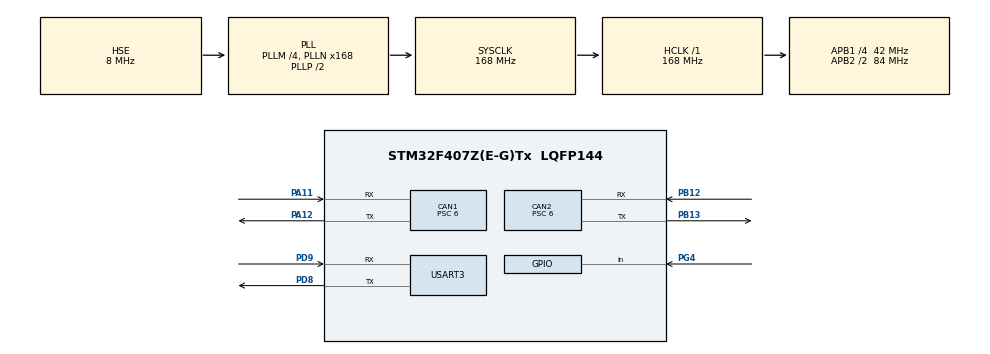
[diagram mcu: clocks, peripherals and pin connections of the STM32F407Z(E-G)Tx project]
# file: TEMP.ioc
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CAN1.BS1=CAN_BS1_3TQ
CAN1.BS2=CAN_BS2_3TQ
CAN1.CalculateBaudRate=1000000
CAN1.CalculateTimeBit=1000
CAN1.CalculateTimeQuantum=142.85714285714286
CAN1.Prescaler=6
CAN1.SJW=CAN_SJW_4TQ
CAN2.BS1=CAN_BS1_3TQ
CAN2.BS2=CAN_BS2_3TQ
CAN2.CalculateBaudRate=1000000
CAN2.CalculateTimeBit=1000
CAN2.CalculateTimeQuantum=142.85714285714286
CAN2.Prescaler=6
CAN2.SJW=CAN_SJW_4TQ
FREERTOS.Tasks01=defaultTask,24,128,StartDefaultTask,Default,NULL,Dynamic,NULL,NULL;myTask02,8,128,TX,As external,NULL,Dynamic,NULL,NULL;myTask03,8,128,CALCULATE,As external,NULL,Dynamic,NULL,NULL;myTask04,8,128,StartTask04,Default,NULL,Dynamic,NULL,NULL
Mcu.Family=STM32F4
Mcu.Name=STM32F407Z(E-G)Tx
Mcu.Package=LQFP144
NVIC.CAN1_RX0_IRQn=true\:5\:0\:false\:false\:true\:true\:true\:true\:true
NVIC.CAN1_TX_IRQn=true\:5\:0\:false\:false\:true\:true\:true\:true\:true
NVIC.CAN2_RX0_IRQn=true\:5\:0\:false\:false\:true\:true\:true\:true\:true
NVIC.CAN2_TX_IRQn=true\:5\:0\:false\:false\:true\:true\:true\:true\:true
NVIC.PriorityGroup=NVIC_PRIORITYGROUP_4
NVIC.TIM1_UP_TIM10_IRQn=true\:15\:0\:false\:false\:true\:false\:false\:true\:true
NVIC.TimeBase=TIM1_UP_TIM10_IRQn
NVIC.TimeBaseIP=TIM1
PA11.Mode=CAN_Activate
PA11.Signal=CAN1_RX
PA12.Mode=CAN_Activate
PA12.Signal=CAN1_TX
PA13.Mode=Serial_Wire
PA13.Signal=SYS_JTMS-SWDIO
PA14.Mode=Serial_Wire
PA14.Signal=SYS_JTCK-SWCLK
PB12.Mode=CAN_Activate
PB12.Signal=CAN2_RX
PB13.Mode=CAN_Activate
PB13.Signal=CAN2_TX
PD8.Mode=Asynchronous
PD8.Signal=USART3_TX
PD9.Mode=Asynchronous
PD9.Signal=USART3_RX
PG4.Signal=GPIO_Input
PH0-OSC_IN.Mode=HSE-External-Oscillator
PH0-OSC_IN.Signal=RCC_OSC_IN
PH1-OSC_OUT.Mode=HSE-External-Oscillator
PH1-OSC_OUT.Signal=RCC_OSC_OUT
ProjectManager.HeapSize=0x200
ProjectManager.StackSize=0x400
ProjectManager.TargetToolchain=MDK-ARM V5.32
RCC.48MHZClocksFreq_Value=84000000
RCC.AHBFreq_Value=168000000
RCC.APB1CLKDivider=RCC_HCLK_DIV4
RCC.APB1Freq_Value=42000000
RCC.APB1TimFreq_Value=84000000
RCC.APB2CLKDivider=RCC_HCLK_DIV2
RCC.APB2Freq_Value=84000000
RCC.APB2TimFreq_Value=168000000
RCC.CortexFreq_Value=168000000
RCC.HCLKFreq_Value=168000000
RCC.HSE_VALUE=8000000
RCC.HSI_VALUE=16000000
RCC.LSE_VALUE=32768
RCC.PLLM=4
RCC.PLLN=168
RCC.PLLSourceVirtual=RCC_PLLSOURCE_HSE
RCC.SYSCLKFreq_VALUE=168000000
RCC.SYSCLKSource=RCC_SYSCLKSOURCE_PLLCLK
RCC.VCOOutputFreq_Value=336000000
USART3.VirtualMode=VM_ASYNC
VP_FREERTOS_VS_CMSIS_V2.Mode=CMSIS_V2
VP_SYS_VS_tim1.Mode=TIM1
board=custom

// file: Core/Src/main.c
/* USER CODE BEGIN Header */
/**
  ******************************************************************************
  * @file           : main.c
  * @brief          : Main program body
  ******************************************************************************
  * @attention
  *
  * Copyright (c) 2024 STMicroelectronics.
  * All rights reserved.
  *
  * This software is licensed under terms that can be found in the LICENSE file
  * in the root directory of this software component.
  * If no LICENSE file comes with this software, it is provided AS-IS.
  *
  ******************************************************************************
  */
/* USER CODE END Header */
#include "main.h"
#include "cmsis_os.h"
#include "can.h"
#include "usart.h"
#include "gpio.h"

/* USER CODE BEGIN Includes */
#include "can_rec.h"
/* USER CODE END Includes */

void SystemClock_Config(void);
void MX_FREERTOS_Init(void);

int main(void)
{

  /* MCU Configuration--------------------------------------------------------*/

  /* Reset of all peripherals, Initializes the Flash interface and the Systick. */
  HAL_Init();

  /* Configure the system clock */
  SystemClock_Config();

  /* Initialize all configured peripherals */
  MX_GPIO_Init();
  MX_CAN1_Init();
  MX_CAN2_Init();
  MX_USART3_UART_Init();
  /* USER CODE BEGIN 2 */
	    my_can_filter_init_recv_all(&hcan1);
    __HAL_CAN_ENABLE_IT(&hcan1, CAN_IT_RX_FIFO0_MSG_PENDING);
//    my_can_filter_init_recv_all(&hcan2);
//    __HAL_CAN_ENABLE_IT(&hcan2, CAN_IT_RX_FIFO0_MSG_PENDING);
  /* USER CODE END 2 */

  /* Init scheduler */
  osKernelInitialize();

  /* Call init function for freertos objects (in cmsis_os2.c) */
  MX_FREERTOS_Init();

  /* Start scheduler */
  osKernelStart();

  /* We should never get here as control is now taken by the scheduler */

  /* Infinite loop */
  while (1)
  {

  }
}

void SystemClock_Config(void)
{
  RCC_OscInitTypeDef RCC_OscInitStruct = {0};
  RCC_ClkInitTypeDef RCC_ClkInitStruct = {0};

  /** Configure the main internal regulator output voltage
  */
  __HAL_RCC_PWR_CLK_ENABLE();
  __HAL_PWR_VOLTAGESCALING_CONFIG(PWR_REGULATOR_VOLTAGE_SCALE1);

  /** Initializes the RCC Oscillators according to the specified parameters
  * in the RCC_OscInitTypeDef structure.
  */
  RCC_OscInitStruct.OscillatorType = RCC_OSCILLATORTYPE_HSE;
  RCC_OscInitStruct.HSEState = RCC_HSE_ON;
  RCC_OscInitStruct.PLL.PLLState = RCC_PLL_ON;
  RCC_OscInitStruct.PLL.PLLSource = RCC_PLLSOURCE_HSE;
  RCC_OscInitStruct.PLL.PLLM = 4;
  RCC_OscInitStruct.PLL.PLLN = 168;
  RCC_OscInitStruct.PLL.PLLP = RCC_PLLP_DIV2;
  RCC_OscInitStruct.PLL.PLLQ = 4;
  if (HAL_RCC_OscConfig(&RCC_OscInitStruct) != HAL_OK)
  {
    Error_Handler();
  }

  /** Initializes the CPU, AHB and APB buses clocks
  */
  RCC_ClkInitStruct.ClockType = RCC_CLOCKTYPE_HCLK|RCC_CLOCKTYPE_SYSCLK
                              |RCC_CLOCKTYPE_PCLK1|RCC_CLOCKTYPE_PCLK2;
  RCC_ClkInitStruct.SYSCLKSource = RCC_SYSCLKSOURCE_PLLCLK;
  RCC_ClkInitStruct.AHBCLKDivider = RCC_SYSCLK_DIV1;
  RCC_ClkInitStruct.APB1CLKDivider = RCC_HCLK_DIV4;
  RCC_ClkInitStruct.APB2CLKDivider = RCC_HCLK_DIV2;

  if (HAL_RCC_ClockConfig(&RCC_ClkInitStruct, FLASH_LATENCY_5) != HAL_OK)
  {
    Error_Handler();
  }
}

void HAL_TIM_PeriodElapsedCallback(TIM_HandleTypeDef *htim)
{
  if (htim->Instance == TIM1) {
    HAL_IncTick();
  }
}

void Error_Handler(void)
{
  __disable_irq();
  while (1)
  {
  }
}

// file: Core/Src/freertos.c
/* USER CODE BEGIN Header */
/**
  ******************************************************************************
  * File Name          : freertos.c
  * Description        : Code for freertos applications
  ******************************************************************************
  * @attention
  *
  * Copyright (c) 2024 STMicroelectronics.
  * All rights reserved.
  *
  * This software is licensed under terms that can be found in the LICENSE file
  * in the root directory of this software component.
  * If no LICENSE file comes with this software, it is provided AS-IS.
  *
  ******************************************************************************
  */
/* USER CODE END Header */

#include "FreeRTOS.h"
#include "task.h"
#include "main.h"
#include "cmsis_os.h"

/* Definitions for defaultTask */
osThreadId_t defaultTaskHandle;
const osThreadAttr_t defaultTask_attributes = {
  .name = "defaultTask",
  .stack_size = 128 * 4,
  .priority = (osPriority_t) osPriorityNormal,
};
/* Definitions for myTask02 */
osThreadId_t myTask02Handle;
const osThreadAttr_t myTask02_attributes = {
  .name = "myTask02",
  .stack_size = 128 * 4,
  .priority = (osPriority_t) osPriorityLow,
};
/* Definitions for myTask03 */
osThreadId_t myTask03Handle;
const osThreadAttr_t myTask03_attributes = {
  .name = "myTask03",
  .stack_size = 128 * 4,
  .priority = (osPriority_t) osPriorityLow,
};
/* Definitions for myTask04 */
osThreadId_t myTask04Handle;
const osThreadAttr_t myTask04_attributes = {
  .name = "myTask04",
  .stack_size = 128 * 4,
  .priority = (osPriority_t) osPriorityLow,
};

void StartDefaultTask(void *argument);
extern void TX(void *argument);
extern void CALCULATE(void *argument);
void StartTask04(void *argument);

void MX_FREERTOS_Init(void); /* (MISRA C 2004 rule 8.1) */

void MX_FREERTOS_Init(void) {

  /* Create the thread(s) */
  /* creation of defaultTask */
  defaultTaskHandle = osThreadNew(StartDefaultTask, NULL, &defaultTask_attributes);

  /* creation of myTask02 */
  myTask02Handle = osThreadNew(TX, NULL, &myTask02_attributes);

  /* creation of myTask03 */
  myTask03Handle = osThreadNew(CALCULATE, NULL, &myTask03_attributes);

  /* creation of myTask04 */
  myTask04Handle = osThreadNew(StartTask04, NULL, &myTask04_attributes);

}

void StartDefaultTask(void *argument)
{
  for(;;)
  {
    osDelay(1);
  }
}

void StartTask04(void *argument)
{
  for(;;)
  {
    osDelay(1);
  }
}
